VERSION ""

NS_ :

BS_:

BU_: MC Charger ELCON Controller Peripheral

// ─────────────────────────────────────────────────────────────────────────────
// Motor Controller → CAN bus  (standard 11-bit frames)
// ─────────────────────────────────────────────────────────────────────────────

BO_ 1616 MC_DC_Bus: 8 MC
 SG_ DC_Voltage : 7|16@0+ (1,0) [0|0] "" Controller
 SG_ DC_Current : 23|16@0+ (1,-5000) [0|0] "0.1A" Controller

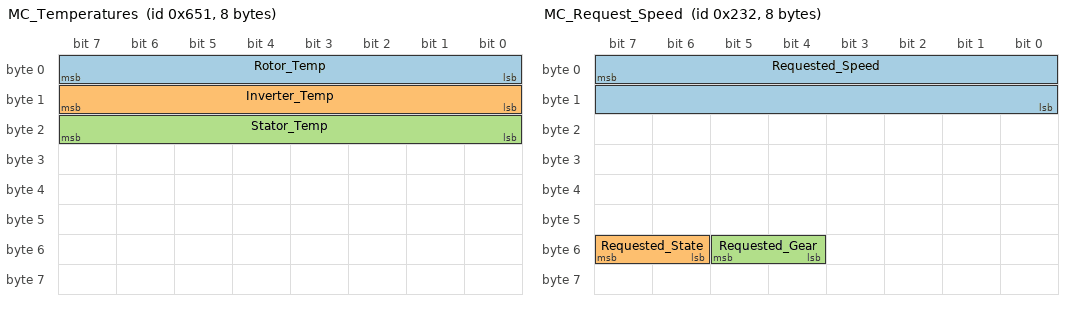
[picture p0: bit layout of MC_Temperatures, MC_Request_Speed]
BO_ 1617 MC_Temperatures: 8 MC
 SG_ Rotor_Temp : 7|8@0+ (1,-40) [-40|215] "degC" Controller
 SG_ Inverter_Temp : 15|8@0+ (1,-40) [-40|215] "degC" Controller
 SG_ Stator_Temp : 23|8@0+ (1,-40) [-40|215] "degC" Controller

BO_ 570 MC_Torque_Actual: 8 MC
 SG_ Torque_Actual : 7|16@0+ (1,-30000) [0|0] "" Controller

BO_ 571 MC_Speed_State: 8 MC
 SG_ Speed_Actual : 7|16@0+ (1,-20000) [0|0] "rpm" Controller
 SG_ Reported_State : 55|4@0+ (1,0) [0|7] "" Controller

BO_ 562 MC_Request_Speed: 8 MC
 SG_ Requested_Speed : 7|16@0+ (1,0) [0|0] "" MC
 SG_ Requested_State : 55|2@0+ (1,0) [0|3] "" MC
 SG_ Requested_Gear : 53|2@0+ (1,0) [0|3] "" MC

BO_ 563 MC_Torque_Request: 8 MC
 SG_ Torque_Requested : 7|16@0+ (1,0) [0|0] "" MC
 SG_ Torque_Limit : 23|16@0+ (1,0) [0|0] "" MC

BO_ 564 MC_Limits: 8 MC
 SG_ Regen_Limit : 7|16@0+ (1,0) [0|0] "" MC
 SG_ Accel_Limit : 23|16@0+ (1,0) [0|0] "" MC

BO_ 565 MC_0x235: 8 MC

BO_ 566 MC_0x236: 8 MC

// ─────────────────────────────────────────────────────────────────────────────
// Controller (pao_console_dial) ↔ Motor Controller
// ─────────────────────────────────────────────────────────────────────────────

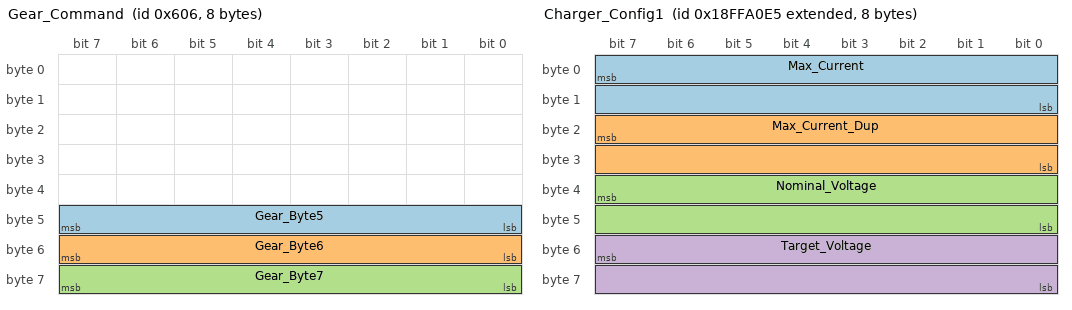
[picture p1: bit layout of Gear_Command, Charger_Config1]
BO_ 1542 Gear_Command: 8 Controller
 SG_ Gear_Byte5 : 47|8@0+ (1,0) [0|255] "" MC
 SG_ Gear_Byte6 : 55|8@0+ (1,0) [0|255] "" MC
 SG_ Gear_Byte7 : 63|8@0+ (1,0) [0|255] "" MC

BO_ 1543 PreCharge_Status: 8 MC
 SG_ PreCharge_Status_Raw : 15|8@0+ (1,0) [0|255] "" Controller

BO_ 1545 Gear_Confirmation: 8 MC

// ─────────────────────────────────────────────────────────────────────────────
// pao_charger → CAN bus  (extended 29-bit frames, broadcast every 5 s)
// ─────────────────────────────────────────────────────────────────────────────

BO_ 2566889701 Charger_Config1: 8 Charger
 SG_ Max_Current : 7|16@0+ (0.1,0) [0|0] "A" Controller
 SG_ Max_Current_Dup : 23|16@0+ (0.1,0) [0|0] "A" Controller
 SG_ Nominal_Voltage : 39|16@0+ (0.1,0) [0|0] "V" Controller
 SG_ Target_Voltage : 55|16@0+ (0.1,0) [0|0] "V" Controller

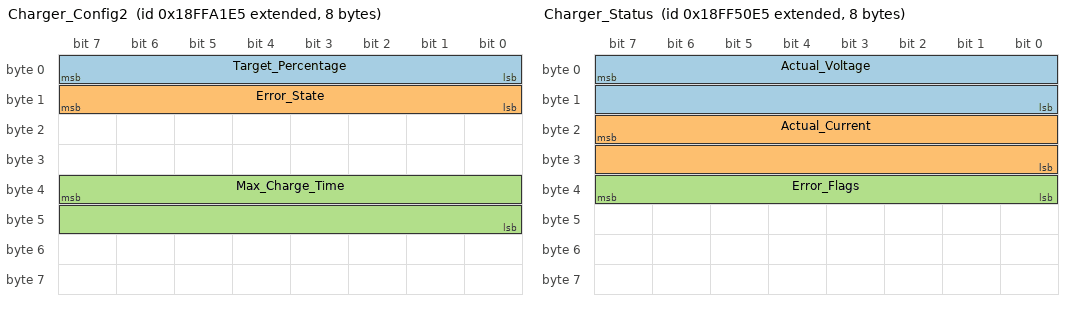
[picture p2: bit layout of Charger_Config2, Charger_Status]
BO_ 2566889957 Charger_Config2: 8 Charger
 SG_ Target_Percentage : 7|8@0+ (1,0) [0|100] "%" Controller
 SG_ Error_State : 15|8@0+ (1,0) [0|255] "" Controller
 SG_ Max_Charge_Time : 39|16@0+ (1,0) [0|65535] "s" Controller

// ─────────────────────────────────────────────────────────────────────────────
// ELCON charger → CAN bus  (extended 29-bit, broadcast every 1 s)
// ─────────────────────────────────────────────────────────────────────────────

BO_ 2566869221 Charger_Status: 8 ELCON
 SG_ Actual_Voltage : 7|16@0+ (0.1,0) [0|0] "V" Controller
 SG_ Actual_Current : 23|16@0+ (0.1,0) [0|0] "A" Controller
 SG_ Error_Flags : 39|8@0+ (1,0) [0|255] "" Controller

// ─────────────────────────────────────────────────────────────────────────────
// Controller → pao_charger  (extended 29-bit, on-demand)
// ─────────────────────────────────────────────────────────────────────────────

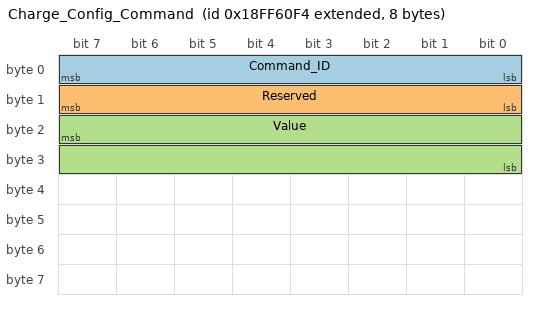
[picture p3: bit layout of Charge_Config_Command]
BO_ 2566873332 Charge_Config_Command: 8 Controller
 SG_ Command_ID : 7|8@0+ (1,0) [0|3] "" Charger
 SG_ Reserved : 15|8@0+ (1,0) [0|0] "" Charger
 SG_ Value : 23|16@0+ (1,0) [0|65535] "" Charger

// ─────────────────────────────────────────────────────────────────────────────
// Comments
// ─────────────────────────────────────────────────────────────────────────────

CM_ BU_ MC "Motor controller (e.g. Rinehart/Cascadia)";
CM_ BU_ Charger "pao_charger — Arduino-based CAN charge manager";
CM_ BU_ ELCON "ELCON hardware charger, J1939 broadcast";
CM_ BU_ Controller "pao_console_dial controller MCU (Feather M0)";
CM_ BU_ Peripheral "pao_console_dial peripheral MCU (ESP32-S3, display)";

CM_ BO_ 1616 "0x650 — DC bus voltage (raw, unit TBD) and current (raw - 5000, unit 0.1 A)";
CM_ BO_ 1617 "0x651 — Motor and inverter temperatures. Wire value minus 40 = degC";
CM_ BO_ 570  "0x23A — Actual torque. Wire value minus 30000";
CM_ BO_ 571  "0x23B — Actual speed (|wire - 20000|) and inverter state (upper nibble of byte 6)";
CM_ BO_ 562  "0x232 — Speed/state/gear requests. State in bits[7:6] of byte 6; gear in bits[5:4]";
CM_ BO_ 563  "0x233 — Requested torque and torque limit";
CM_ BO_ 564  "0x234 — Regen and acceleration limits";
CM_ BO_ 565  "0x235 — Unimplemented (no signals parsed)";
CM_ BO_ 566  "0x236 — Unimplemented (no signals parsed)";
CM_ BO_ 1542 "0x606 — Gear command. NEUTRAL: all 0. DRIVE: byte6=0xFF byte7=0x88. REVERSE: byte6=0x88 byte7=0xFF. PARK: byte5=0xFF bytes6-7=0x00";
CM_ BO_ 1543 "0x607 — Pre-charge contactor ready. byte1: 0x88=ready, 0xFF=not ready";
CM_ BO_ 1545 "0x609 — Gear change confirmation from motor controller (no payload parsed)";
CM_ BO_ 2566889701 "0x18FFA0E5 — pao_charger config broadcast 1. bytes[0:1]=maxCurrent, bytes[2:3]=maxCurrent(dup), bytes[4:5]=nominalVoltage, bytes[6:7]=targetVoltage. All in 0.1 V / 0.1 A";
CM_ BO_ 2566889957 "0x18FFA1E5 — pao_charger config broadcast 2. Target_Percentage is the configured charge LIMIT (e.g. 95), not actual SOC. bytes[2:3] not used. Max_Charge_Time in seconds";
CM_ BO_ 2566869221 "0x18FF50E5 — ELCON hardware charger status. Actual voltage and current from charger output. Error_Flags bitmask at byte 4";
CM_ BO_ 2566873332 "0x18FF60F4 — Charge config command from pao_console_dial to pao_charger. Sent repeatedly until charger confirms via 0x18FFA0E5/0x18FFA1E5 broadcast. Value encoding depends on Command_ID";

CM_ SG_ 571 Reported_State "0=Initializing, 1=Disabled, 2=Standby/Ready, 3=Enabled, 4=PowerDown, 5=Fault, 6=CriticalFault, 7=LOS";
CM_ SG_ 1543 PreCharge_Status_Raw "0x88 = pre-charge ready (HIGH); 0xFF = not ready (LOW)";
CM_ SG_ 2566889957 Target_Percentage "Configured charge limit percent (0-100). NOT current SOC. Estimated SOC = (Actual_Voltage / Target_Voltage) * Target_Percentage";
CM_ SG_ 2566873332 Command_ID "1=set_max_time, 2=set_target_pct, 3=set_target_amps";
CM_ SG_ 2566873332 Value "cmd=1: seconds (uint16). cmd=2: target_pct * 10 (e.g. 950 = 95%). cmd=3: amps in 0.1 A units (e.g. 150 = 15.0 A)";

// ─────────────────────────────────────────────────────────────────────────────
// Value descriptions
// ─────────────────────────────────────────────────────────────────────────────

 0 "Initializing"
 1 "Disabled"
 2 "Standby"
 3 "Enabled"
 4 "PowerDown"
 5 "Fault"
 6 "CriticalFault"
 7 "LOS" ;

 1 "SetMaxTime"
 2 "SetTargetPct"
 3 "SetTargetAmps" ;
